# CY8C4245AXI_483 register map
File version: 0.1
PSoC 4200
Registers are 32-bit, read-write, no defined reset value unless marked. A register's access mark holds for its fields unless they carry their own. Offsets are from the block's base; lines under a group give offsets from that group; [hi:lo] are bit positions; {n}, {i} and the like mark numbered series; 'fields as' and 'values as' point back to an identical list; <NAME> marks a mode.

## Memory map
0x00000000 PWM_PIEZO
0x00000000 LPComp_movement_detector — Low Power Comparator

## PWM_PIEZO
Base 0x00000000
0x40050108 COUNTER — Current counter value
0x4005010C CC — Compare / capture value
0x40050110 CC_BUF — Compare / capture buffer value
0x40050114 PERIOD — Period value
0x40050118 PERIOD_BUF — Period buffer value

## LPComp_movement_detector — Low Power Comparator
Base 0x00000000
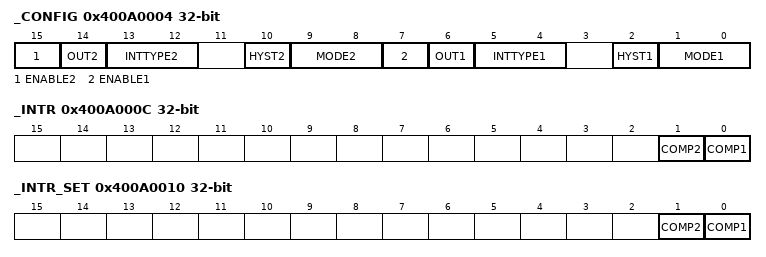
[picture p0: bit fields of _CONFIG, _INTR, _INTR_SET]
0x400A0004 _CONFIG — LPCOMP configuration
  [15] ENABLE2 — Enable comparator #2
    0=DISABLE (Comparator disabled); 1=ENABLE (Comparator enabled)
  [14] OUT2 ro — Current output value of the comparator #2
  [13:12] INTTYPE2 — Sets which edge will trigger an IRQ for the comparator #2
    0=DISABLE (Disabled); 1=RISING (Rising edge); 2=FALLING (Falling edge); 3=BOTH (Both rising and falling edges)
  [10] HYST2 — Selects hysteresis (10mV) for the comparator #2
    0=ENABLE (Hysteresis enabled); 1=DISABLE (Hysteresis disabled)
  [9:8] MODE2 — Selects speed for the comparator #2
    0=MED (Medium speed); 1=FAST (Fast speed); 2=SLOW (Slow speed)
  [7] ENABLE1 — Enable comparator #1
    values as ENABLE2
  [6] OUT1 ro — Current output value of the comparator
  [5:4] INTTYPE1 — Sets which edge will trigger an IRQ for the comparator #1
    values as INTTYPE2
  [2] HYST1 — Selects hysteresis (10mV) for the comparator #1
    values as HYST2
  [1:0] MODE1 — Selects speed for the comparator #1
    values as MODE2
0x400A000C _INTR — LPCOMP interrupt
  [1] COMP2 — Comparator #2 Interrupt: hardware sets this interrupt when comparator 0 triggers. Write with '1' to clear bit.
  [0] COMP1 — Comparator #1 Interrupt: hardware sets this interrupt when comparator 0 triggers. Write with '1' to clear bit.
0x400A0010 _INTR_SET — LPCOMP interrupt set register
  [1] COMP2 — Write with '1' to set corresponding bit in interrupt request register.
  [0] COMP1 — Write with '1' to set corresponding bit in interrupt request register.
0x400AFF00 _TRIM_A — LPCOMP trim A
0x400AFF04 _TRIM_B — LPCOMP trim B
